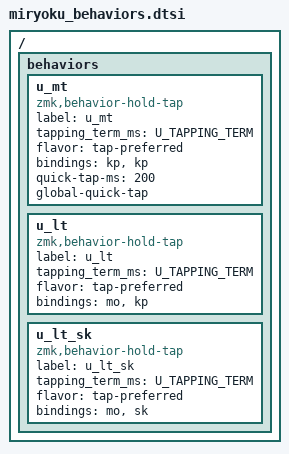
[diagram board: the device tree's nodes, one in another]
// Copyright 2022 Manna Harbour
// https://github.com/manna-harbour/miryoku

/ {
  behaviors {
    u_mt: u_mt {
      compatible = "zmk,behavior-hold-tap";
      label = "u_mt";
      #binding-cells = <2>;
      tapping_term_ms = <U_TAPPING_TERM>;
      flavor = "tap-preferred";
      bindings = <&kp>, <&kp>;
      quick-tap-ms = <200>;
      global-quick-tap;
    };
    u_lt: u_lt {
      compatible = "zmk,behavior-hold-tap";
      label = "u_lt";
      #binding-cells = <2>;
      tapping_term_ms = <U_TAPPING_TERM>;
      flavor = "tap-preferred";
      bindings = <&mo>, <&kp>;
    };
    u_lt_sk: u_lt_sk {
      compatible = "zmk,behavior-hold-tap";
      label = "u_lt_sk";
      #binding-cells = <2>;
      tapping_term_ms = <U_TAPPING_TERM>;
      flavor = "tap-preferred";
      bindings = <&mo>, <&sk>;
    };
  };
};
